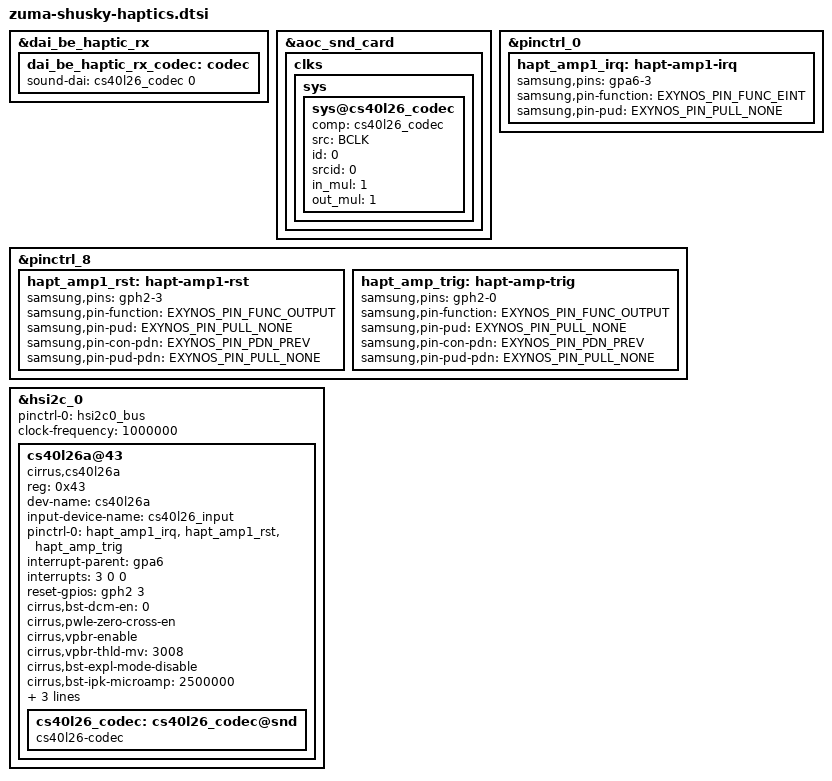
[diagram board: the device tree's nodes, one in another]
// SPDX-License-Identifier: GPL-2.0-only
/*
 * Google Zuma cs40l26 device tree source
 *
 * Copyright (c) 2022 Google, LLC
 *		https://www.google.com
 *
*/

#include <dt-bindings/gpio/gpio.h>
#include <dt-bindings/pinctrl/samsung.h>

&dai_be_haptic_rx {
	dai_be_haptic_rx_codec: codec {
		sound-dai = <&cs40l26_codec 0>;
	};
};

&aoc_snd_card {
	clks {
		sys {
			sys@cs40l26_codec {
				comp = <&cs40l26_codec>;
				src = "BCLK";
				/* clk id */
				id = <0>;
				/* clk source */
				srcid = <0>;
				/* in clk multiple */
				in_mul = <1>;
				/* out clk multiple */
				out_mul = <1>;
			};

		};
	};
};

/* GPIO_ALIVE*/
&pinctrl_0 {
	hapt_amp1_irq: hapt-amp1-irq {
		samsung,pins = "gpa6-3"; /* XEINT_11 */
		samsung,pin-function = <EXYNOS_PIN_FUNC_EINT>;
		samsung,pin-pud = <EXYNOS_PIN_PULL_NONE>;
	};
};

/* GPIO_HSI1 */
&pinctrl_8 {
	hapt_amp1_rst: hapt-amp1-rst {
		samsung,pins = "gph2-3"; /* XHSI1_GPIO13 */
		samsung,pin-function = <EXYNOS_PIN_FUNC_OUTPUT>;
		samsung,pin-pud = <EXYNOS_PIN_PULL_NONE>;
		samsung,pin-con-pdn = <EXYNOS_PIN_PDN_PREV>;
		samsung,pin-pud-pdn = <EXYNOS_PIN_PULL_NONE>;
	};

	hapt_amp_trig: hapt-amp-trig {
		samsung,pins = "gph2-0"; /* XHSI1_GPIO10 */
		samsung,pin-function = <EXYNOS_PIN_FUNC_OUTPUT>;
		samsung,pin-pud = <EXYNOS_PIN_PULL_NONE>;
		samsung,pin-con-pdn = <EXYNOS_PIN_PDN_PREV>;
		samsung,pin-pud-pdn = <EXYNOS_PIN_PULL_NONE>;
	};
};

&hsi2c_0 {
	#address-cells = <1>;
	#size-cells = <0>;
	status = "okay";

	pinctrl-names = "default";
	pinctrl-0 = <&hsi2c0_bus>;

	clock-frequency = <1000000>;

	cs40l26a@43 {
		compatible = "cirrus,cs40l26a";
		reg = <0x43>;
		dev-name = "cs40l26a";  /* sysfs folder name */
		input-device-name = "cs40l26_input";    /* input device name */

		pinctrl-names = "default";
		pinctrl-0 = <&hapt_amp1_irq &hapt_amp1_rst &hapt_amp_trig>;

		interrupt-parent = <&gpa6>;
		interrupts = <3 0 0>;

		reset-gpios = <&gph2 3 0>;

		cirrus,bst-dcm-en = <0>;
		cirrus,pwle-zero-cross-en;
		cirrus,vpbr-enable;
		cirrus,vpbr-thld-mv = <3008>;		/* 3.0V */
		cirrus,bst-expl-mode-disable;
		cirrus,bst-ipk-microamp = <2500000>;	/* 2.5A */
		cirrus,boost-ctl-microvolt = <11000000>;/* 11V */
		cirrus,f0-default = <0x244000>;		/* 145 Hz */
		cirrus,redc-default = <0x68000>;	/* 13 Ohm */

		status = "okay";

		cs40l26_codec: cs40l26_codec@snd {
			#sound-dai-cells = <1>;
			compatible = "cs40l26-codec";
			status = "okay";
		};
	};
};
